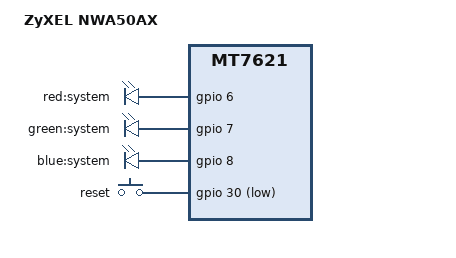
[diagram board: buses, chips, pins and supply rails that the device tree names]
#include "mt7621_zyxel_nwa-ax.dtsi"

#include <dt-bindings/gpio/gpio.h>
#include <dt-bindings/input/input.h>

/ {
	compatible = "zyxel,nwa50ax", "mediatek,mt7621-soc";
	model = "ZyXEL NWA50AX";

	aliases {
		led-boot = &led_system_green;
		led-failsafe = &led_system_red;
		led-running = &led_system_green;
		led-upgrade = &led_system_red;
	};

	leds {
		compatible = "gpio-leds";

		led_system_red: system_red {
			label = "red:system";
			gpios = <&gpio 6 GPIO_ACTIVE_HIGH>;
		};

		led_system_green: system_green {
			label = "green:system";
			gpios = <&gpio 7 GPIO_ACTIVE_HIGH>;
		};

		system_blue {
			label = "blue:system";
			gpios = <&gpio 8 GPIO_ACTIVE_HIGH>;
		};
	};

	keys {
		compatible = "gpio-keys";

		reset {
			label = "reset";
			gpios = <&gpio 30 GPIO_ACTIVE_LOW>;
			linux,code = <KEY_RESTART>;
		};
	};
};

&ethernet {
	pinctrl-0 = <&mdio_pins>, <&rgmii1_pins>;
};

&state_default {
	gpio {
		groups = "uart3", "rgmii2";
		function = "gpio";
	};
};
